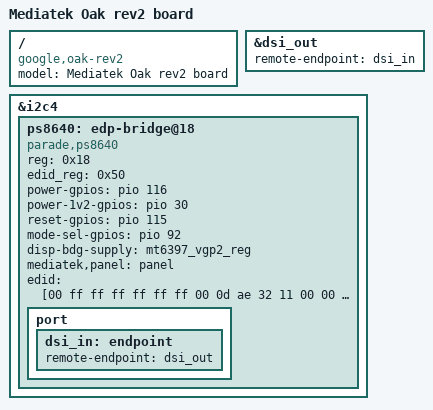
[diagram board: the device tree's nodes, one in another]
/*
 * Copyright 2015 MediaTek Inc.
 * Author: Eddie Huang <eddie.huang@mediatek.com>
 *
 * This program is free software; you can redistribute it and/or modify
 * it under the terms of the GNU General Public License version 2 as
 * published by the Free Software Foundation.
 *
 * This program is distributed in the hope that it will be useful,
 * but WITHOUT ANY WARRANTY; without even the implied warranty of
 * MERCHANTABILITY or FITNESS FOR A PARTICULAR PURPOSE.  See the
 * GNU General Public License for more details.
 */

/dts-v1/;
#include "mt8173-oak.dtsi"

/ {
	model = "Mediatek Oak rev2 board";
	compatible = "google,oak-rev2", "google,oak", "mediatek,mt8173";
};

&dsi_out {
	remote-endpoint = <&dsi_in>;
};

&i2c4 {
	ps8640: edp-bridge@18 {
		compatible = "parade,ps8640";
		reg = <0x18>;
		edid_reg = <0x50>;
		power-gpios = <&pio 116 GPIO_ACTIVE_HIGH>;
		power-1v2-gpios = <&pio 30 GPIO_ACTIVE_HIGH>;
		reset-gpios = <&pio 115 GPIO_ACTIVE_HIGH>;
		mode-sel-gpios = <&pio 92 GPIO_ACTIVE_HIGH>;
		disp-bdg-supply = <&mt6397_vgp2_reg>;
		mediatek,panel = <&panel>;
		edid = [00 ff ff ff ff ff ff 00 0d ae 32 11 00 00 00 00
			13 17 01 04 95 1a 0e 78 02 14 35 92 55 53 95 29
			24 50 54 00 00 00 01 01 01 01 01 01 01 01 01 01
			01 01 01 01 01 01 da 1d 56 e2 50 00 20 30 88 1e
			8c 00 00 90 10 00 00 18 00 00 00 fe 00 4e 31 31
			36 42 47 45 2d 45 41 32 0a 20 00 00 00 fe 00 43
			4d 4e 0a 20 20 20 20 20 20 20 20 20 00 00 00 fe
			00 4e 31 31 36 42 47 45 2d 45 41 32 0a 20 00 48];
		port {
			dsi_in: endpoint {
				remote-endpoint = <&dsi_out>;
			};
		};
	};
};
